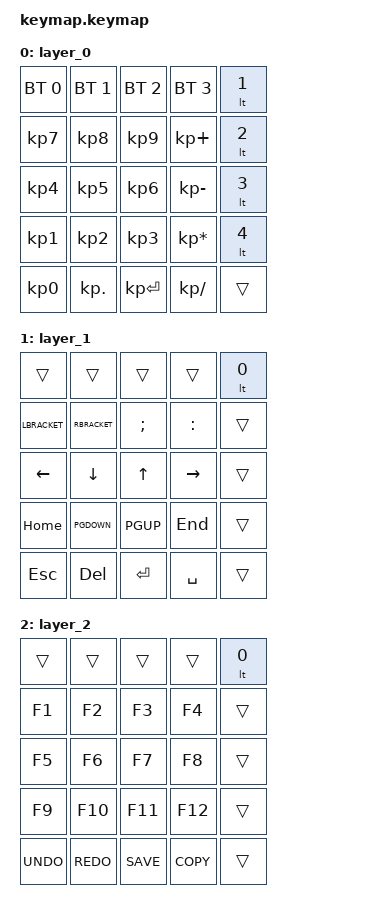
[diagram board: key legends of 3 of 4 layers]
// Define the keymap for your macropad
/ {
    keymap {
        compatible = "zmk,keymap";

        // Layer 0 (Number Pad & Bluetooth Device Selection)
        layer_0 {
            bindings = <
                &bt BT_SEL 0  &bt BT_SEL 1  &bt BT_SEL 2  &bt BT_SEL 3  &lt 1
                &kp KP_7      &kp KP_8      &kp KP_9      &kp KP_PLUS   &lt 2
                &kp KP_4      &kp KP_5      &kp KP_6      &kp KP_MINUS  &lt 3
                &kp KP_1      &kp KP_2      &kp KP_3      &kp KP_ASTERISK &lt 4
                &kp KP_0      &kp KP_DOT    &kp KP_ENTER   &kp KP_SLASH  &trans
            >;
        };

        // Layer 1 (Special Characters & Navigation)
        layer_1 {
            bindings = <
                &trans        &trans       &trans       &trans       &lt 0
                &kp LBRACKET  &kp RBRACKET &kp SEMI     &kp COLON    &trans
                &kp LEFT      &kp DOWN     &kp UP       &kp RIGHT    &trans
                &kp HOME      &kp PGDOWN   &kp PGUP     &kp END      &trans
                &kp ESC       &kp DELETE   &kp ENTER    &kp SPACE    &trans
            >;
        };

        // Layer 2 (SolidWorks Shortcuts)
        layer_2 {
            bindings = <
                &trans        &trans       &trans       &trans       &lt 0
                &kp F1        &kp F2       &kp F3       &kp F4       &trans
                &kp F5        &kp F6       &kp F7       &kp F8       &trans
                &kp F9        &kp F10      &kp F11      &kp F12      &trans
                &kp UNDO      &kp REDO     &kp SAVE     &kp COPY     &trans
            >;
        };

        // Layer 3 (Figma/QtDesigner Shortcuts)
        layer_3 {
            bindings = <
                &trans        &trans       &trans       &trans       &lt 0
                &kp CTRL+C    &kp CTRL+V   &kp CTRL+Z   &kp CTRL+Y   &trans
                &kp SHIFT+TAB &kp TAB      &kp ARROW_UP &kp ARROW_DOWN &trans
                &kp LEFT      &kp DOWN     &kp UP       &kp RIGHT    &trans
                &kp CTRL+S    &kp CTRL+O   &kp CTRL+P   &kp CTRL+D   &trans
            >;
        };
    };
};
